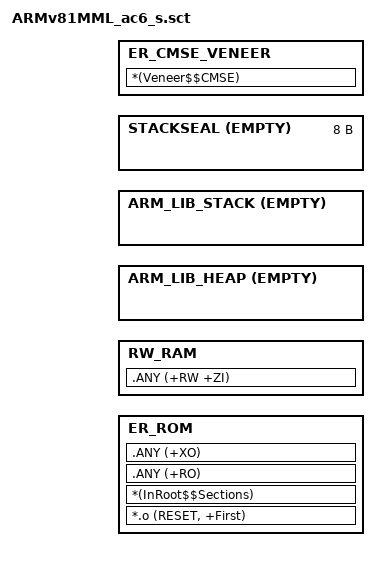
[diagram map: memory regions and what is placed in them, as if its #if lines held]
#! armclang -E --target=arm-arm-none-eabi -march=armv8.1-m.main -xc -mcmse
; command above MUST be in first line (no comment above!)

;/* 
; *
; * MIT License
; * Copyright (c) 2025 ARM Limited.
; * 
; * Permission is hereby granted, free of charge, to any person obtaining a copy
; * of this software and associated documentation files (the "Software"), to deal
; * in the Software without restriction, including without limitation the rights
; * to use, copy, modify, merge, publish, distribute, sublicense, and/or sell
; * copies of the Software, and to permit persons to whom the Software is
; * furnished to do so, subject to the following conditions:
; * 
; * The above copyright notice and this permission notice shall be included in all
; * copies or substantial portions of the Software.
; * 
; * THE SOFTWARE IS PROVIDED "AS IS", WITHOUT WARRANTY OF ANY KIND, EXPRESS OR
; * IMPLIED, INCLUDING BUT NOT LIMITED TO THE WARRANTIES OF MERCHANTABILITY,
; * FITNESS FOR A PARTICULAR PURPOSE AND NONINFRINGEMENT. IN NO EVENT SHALL THE
; * AUTHORS OR COPYRIGHT HOLDERS BE LIABLE FOR ANY CLAIM, DAMAGES OR OTHER
; * LIABILITY, WHETHER IN AN ACTION OF CONTRACT, TORT OR OTHERWISE, ARISING FROM,
; * OUT OF OR IN CONNECTION WITH THE SOFTWARE OR THE USE OR OTHER DEALINGS IN THE
; * SOFTWARE.
; * 
; */

;Note: Add '-mcmse' to first line if your software model is "Secure Mode".

#include "../../../region_defs.h"



/*----------------------------------------------------------------------------
  User Stack & Heap boundary definition
 *----------------------------------------------------------------------------*/
#define __STACK_TOP    (__RAM_BASE_S + __RAM_SIZE_S - __STACKSEAL_SIZE) /* starts at end of RAM - 8 byte stack seal */
#define __HEAP_BASE    (AlignExpr(+0, 8))                           /* starts after RW_RAM section, 8 byte aligned */

/* ----------------------------------------------------------------------------
  Stack seal size definition
 *----------------------------------------------------------------------------*/
#if defined (__ARM_FEATURE_CMSE) && (__ARM_FEATURE_CMSE == 3U)
#define __STACKSEAL_SIZE   ( 8 )
#else
#define __STACKSEAL_SIZE   ( 0 )
#endif


/*----------------------------------------------------------------------------
  Region base & size definition
 *----------------------------------------------------------------------------*/
#if defined (__ARM_FEATURE_CMSE) && (__ARM_FEATURE_CMSE == 3U)
#if defined (__CMSEVENEER_BASE) && (__CMSEVENEER_BASE == 0xFFFFFFFF)
#define __CV_BASE          ( __ROM_BASE_S + __ROM_SIZE_S - __CMSEVENEER_SIZE )
#else
#define __CV_BASE          ( __CMSEVENEER_BASE )
#endif
#define __CV_SIZE          ( __CMSEVENEER_SIZE )
#else
#define __CV_SIZE          ( 0 )
#endif

#define __RO_BASE          ( __ROM_BASE_S )
#define __RO_SIZE          ( __ROM_SIZE_S - __CV_SIZE )  


#define __RW_BASE          ( __RAM_BASE_S )
#define __RW_SIZE          ( __RAM_SIZE_S - __STACK_SIZE - __HEAP_SIZE )


/*----------------------------------------------------------------------------
  Scatter Region definition
 *----------------------------------------------------------------------------*/
LR_ROM __RO_BASE __RO_SIZE  {                       ; load region size_region
  ER_ROM __RO_BASE __RO_SIZE  {                     ; load address = execution address
   *.o (RESET, +First)
   *(InRoot$$Sections)
   .ANY (+RO)
   .ANY (+XO)
  }

  RW_RAM __RW_BASE __RW_SIZE  {                     ; RW data
   .ANY (+RW +ZI)
  }

#if __HEAP_SIZE > 0
  ARM_LIB_HEAP  __HEAP_BASE EMPTY  __HEAP_SIZE  {   ; Reserve empty region for heap
  }
#endif

  ARM_LIB_STACK __STACK_TOP EMPTY -__STACK_SIZE {   ; Reserve empty region for stack
  }

#if defined (__ARM_FEATURE_CMSE) && (__ARM_FEATURE_CMSE == 3U)
  STACKSEAL +0 EMPTY __STACKSEAL_SIZE {             ; Reserve empty region for stack seal immediately after stack
  }
#endif
}

#if defined (__ARM_FEATURE_CMSE) && (__ARM_FEATURE_CMSE == 3U)
LR_CMSE_VENEER __CV_BASE ALIGN 32 __CV_SIZE  {      ; own load/execution region for CMSE Veneers
  ER_CMSE_VENEER __CV_BASE __CV_SIZE  {
   *(Veneer$$CMSE)
  }
}
#endif


